# RK3399-AP register map
File version: 1
CPU: CA7 r0p1, little endian, MPU, FPU, I-cache, D-cache, VTOR, 4 interrupt priority bits, 0 interrupts
Registers are 32-bit, read-write, reset 0x0 unless marked. A register's access mark holds for its fields unless they carry their own. Offsets are from the block's base; [hi:lo] are bit positions; 'fields as' and 'values as' point back to an identical list.

## GRF (part 2 of 4)
Base 0xFF770000
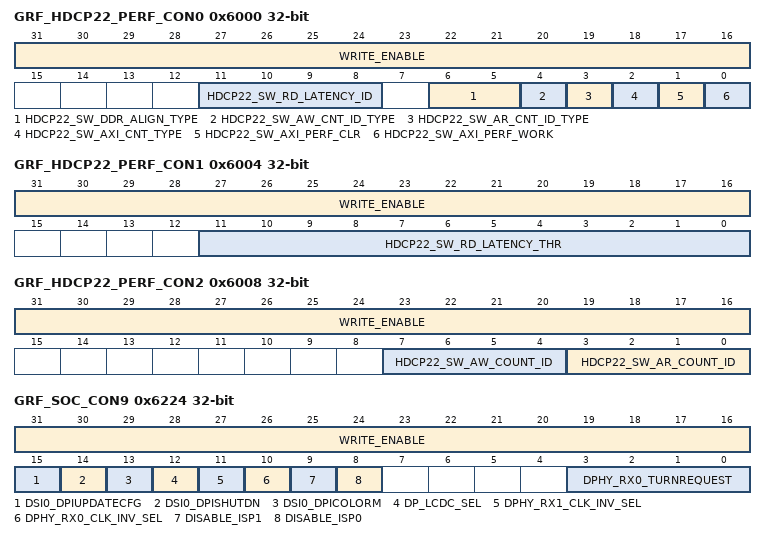
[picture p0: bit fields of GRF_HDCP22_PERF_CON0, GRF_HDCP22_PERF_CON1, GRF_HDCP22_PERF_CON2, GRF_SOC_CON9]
0x6000 GRF_HDCP22_PERF_CON0 — hdcp performance monitor control register
  [31:16] WRITE_ENABLE — bit0~15 write enable When bit 16=1, bit 0 can be written by software . When bit 16=0, bit 0 cannot be written by software; When bit 17=1, bit 1 can be written by software . When bit 17=0, bit 1 cannot be written by software; ...... When bit 31=1, bit 15 can be written by software . When bit 31=0, bit 15 cannot be written by software;
  [11:8] HDCP22_SW_RD_LATENCY_ID — Axi read channel id for latency AXI_PERFormance test
  [6:5] HDCP22_SW_DDR_ALIGN_TYPE — 0: 16-Byte align 1: 32-Byte align 2: 64-Byte align 3: 128-Byte align
  [4] HDCP22_SW_AW_CNT_ID_TYPE — 0: count all write channels 1: count sw_aw_count_id write channel only
  [3] HDCP22_SW_AR_CNT_ID_TYPE — axi_perf counter id control 0: count all read channel id 1: count sw_ar_count_id read channel only
  [2] HDCP22_SW_AXI_CNT_TYPE — axi_perf counter type 0: axi transfer test 1: ddr align transfer test
  [1] HDCP22_SW_AXI_PERF_CLR — axi_perf clear bit 0: disable 1: enable
  [0] HDCP22_SW_AXI_PERF_WORK — axi_perf enable bit 0: disable 1: enable
0x6004 GRF_HDCP22_PERF_CON1 — hdcp performance monitor control register
  [31:16] WRITE_ENABLE — bit0~15 write enable When bit 16=1, bit 0 can be written by software . When bit 16=0, bit 0 cannot be written by software; When bit 17=1, bit 1 can be written by software . When bit 17=0, bit 1 cannot be written by software; ...... When bit 31=1, bit 15 can be written by software . When bit 31=0, bit 15 cannot be written by software;
  [11:0] HDCP22_SW_RD_LATENCY_THR — Axi Read latency threshold
0x6008 GRF_HDCP22_PERF_CON2 — hdcp performance monitor control register
  [31:16] WRITE_ENABLE — bit0~15 write enable When bit 16=1, bit 0 can be written by software . When bit 16=0, bit 0 cannot be written by software; When bit 17=1, bit 1 can be written by software . When bit 17=0, bit 1 cannot be written by software; ...... When bit 31=1, bit 15 can be written by software . When bit 31=0, bit 15 cannot be written by software;
  [7:4] HDCP22_SW_AW_COUNT_ID — When sw_aw_cnt_id_type=1, only count the id designated by sw_aw_count_id
  [3:0] HDCP22_SW_AR_COUNT_ID — When sw_ar_cnt_id_type=1, only count the id designated by sw_ar_count_id
0x600C GRF_HDCP22_PERF_RD_MAX_LATENCY_NUM — hdcp performance monitor status register
  [12:0] RD_MAX_LATENCY_R — axi read max latency output
0x6010 GRF_HDCP22_PERF_RD_LATENCY_SAMP_NUM — hdcp performance monitor status register
  [26:0] RD_LATENCY_SAMP_R — AXI read latency total sample number
0x6014 GRF_HDCP22_PERF_RD_LATENCY_ACC_NUM — hdcp performance monitor status register
  [31:0] RD_LATENCY_ACC_CNT_R — AXI read latency (>sw_rd_latency_thr) total number
0x6018 GRF_HDCP22_PERF_RD_AXI_TOTAL_BYTE — hdcp performance monitor status register
  [31:0] RD_AXI_TOTAL_BYTE — AXI active total read bytes/ddr align read bytes
0x601C GRF_HDCP22_PERF_WR_AXI_TOTAL_BYTE — hdcp performance monitor status register
  [31:0] WR_AXI_TOTAL_BYTE — AXI active total write bytes/ddr align write bytes
0x6020 GRF_HDCP22_PERF_WORKING_CNT — hdcp performance monitor status register
  [31:0] WORKING_CNT_R — working counter
0x6224 GRF_SOC_CON9 — SoC control register 9
  [31:16] WRITE_ENABLE — bit0~15 write enable When bit 16=1, bit 0 can be written by software . When bit 16=0, bit 0 cannot be written by software; When bit 17=1, bit 1 can be written by software . When bit 17=0, bit 1 cannot be written by software; ...... When bit 31=1, bit 15 can be written by software . When bit 31=0, bit 15 cannot be written by software;
  [15] DSI0_DPIUPDATECFG — DSI host0 dpiupdatecfg bit control
  [14] DSI0_DPISHUTDN — DSI0 dpishutdn bit control
  [13] DSI0_DPICOLORM — DSI0 dpicolorm bit control
  [12] DP_LCDC_SEL — dp lcdc select 1\'b0: vop big 1\'b1: vop little
  [11] DPHY_RX1_CLK_INV_SEL — dphy rx1 clock inveter select bit
  [10] DPHY_RX0_CLK_INV_SEL — dphy rx0 clock inveter select bit
  [9] DISABLE_ISP1 — isp1 disable control
  [8] DISABLE_ISP0 — isp0 disable control
  [3:0] DPHY_RX0_TURNREQUEST — dphy rx0 runrequest port control
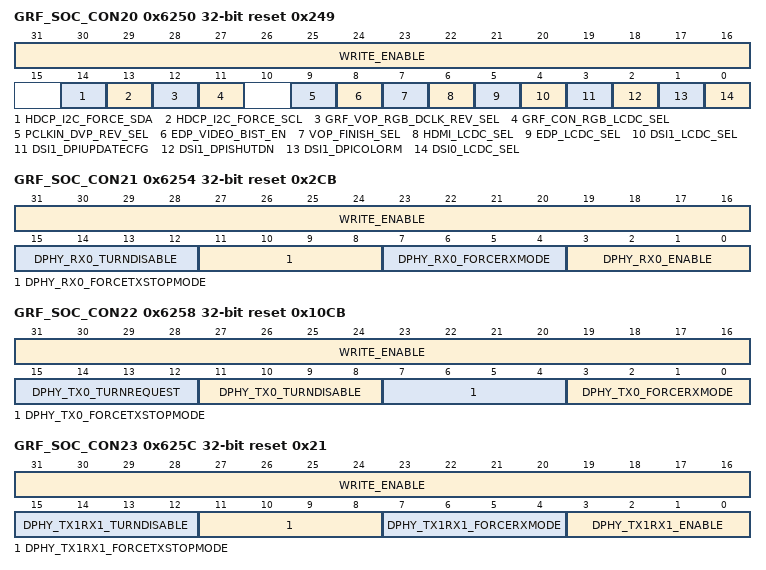
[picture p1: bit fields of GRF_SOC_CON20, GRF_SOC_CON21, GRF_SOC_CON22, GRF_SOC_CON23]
0x6250 GRF_SOC_CON20 reset 0x249 — SoC control register 20
  [31:16] WRITE_ENABLE — bit0~15 write enable When bit 16=1, bit 0 can be written by software . When bit 16=0, bit 0 cannot be written by software; When bit 17=1, bit 1 can be written by software . When bit 17=0, bit 1 cannot be written by software; ...... When bit 31=1, bit 15 can be written by software . When bit 31=0, bit 15 cannot be written by software;
  [14] HDCP_I2C_FORCE_SDA — hdcp_i2c_force_sda bit control
  [13] HDCP_I2C_FORCE_SCL — hdcp_i2c_force_scl control
  [12] GRF_VOP_RGB_DCLK_REV_SEL — dclk phase selct 0: 0 degree 1: 180 degree
  [11] GRF_CON_RGB_LCDC_SEL — vop select 1\'b0: vop big 1\'b1: vop little
  [9] PCLKIN_DVP_REV_SEL — pclkin dvp clock select 0: not invet phase 1: invert phase
  [8] EDP_VIDEO_BIST_EN — edp video bist enable 1: enable 0: disable
  [7] VOP_FINISH_SEL — vop finish select 1\'b0: vop big 1\'b1: vop little
  [6] HDMI_LCDC_SEL — hdmi lcdc select 1\'b0: vop big 1\'b1: vop little
  [5] EDP_LCDC_SEL — edp lcdc select 1\'b0: vop big 1\'b1: vop little
  [4] DSI1_LCDC_SEL — dsi1 lcdc select 1\'b0: vop big 1\'b1: vop little
  [3] DSI1_DPIUPDATECFG — dsi1 dpiupdatecfg bit control
  [2] DSI1_DPISHUTDN — dsi1 dpishutdn bit control
  [1] DSI1_DPICOLORM — dsi1 dpicolorm bit control
  [0] DSI0_LCDC_SEL — dsi0 vol select bit 1\'b0: vop big 1\'b1: vop little
0x6254 GRF_SOC_CON21 reset 0x2CB — SoC control register 21
  [31:16] WRITE_ENABLE — bit0~15 write enable When bit 16=1, bit 0 can be written by software . When bit 16=0, bit 0 cannot be written by software; When bit 17=1, bit 1 can be written by software . When bit 17=0, bit 1 cannot be written by software; ...... When bit 31=1, bit 15 can be written by software . When bit 31=0, bit 15 cannot be written by software;
  [15:12] DPHY_RX0_TURNDISABLE — dphy_rx0_turndisable bit control
  [11:8] DPHY_RX0_FORCETXSTOPMODE — dphy_rx0_forcetxstopmode bit control
  [7:4] DPHY_RX0_FORCERXMODE — dphy_rx0_forcerxmode bit control
  [3:0] DPHY_RX0_ENABLE — dphy_rx0_enable bit control
0x6258 GRF_SOC_CON22 reset 0x10CB — SoC control register 22
  [31:16] WRITE_ENABLE — bit0~15 write enable When bit 16=1, bit 0 can be written by software . When bit 16=0, bit 0 cannot be written by software; When bit 17=1, bit 1 can be written by software . When bit 17=0, bit 1 cannot be written by software; ...... When bit 31=1, bit 15 can be written by software . When bit 31=0, bit 15 cannot be written by software;
  [15:12] DPHY_TX0_TURNREQUEST — dphy_tx0_turnrequest bit control
  [11:8] DPHY_TX0_TURNDISABLE — dphy_tx0_turndisable bit control
  [7:4] DPHY_TX0_FORCETXSTOPMODE — dphy_tx0_forcetxstopmode bit control
  [3:0] DPHY_TX0_FORCERXMODE — dphy_tx0_forcerxmode bit control
0x625C GRF_SOC_CON23 reset 0x21 — SoC control register 23
  [31:16] WRITE_ENABLE — bit0~15 write enable When bit 16=1, bit 0 can be written by software . When bit 16=0, bit 0 cannot be written by software; When bit 17=1, bit 1 can be written by software . When bit 17=0, bit 1 cannot be written by software; ...... When bit 31=1, bit 15 can be written by software . When bit 31=0, bit 15 cannot be written by software;
  [15:12] DPHY_TX1RX1_TURNDISABLE — dphy_tx1rx1_turndisable bit control
  [11:8] DPHY_TX1RX1_FORCETXSTOPMODE — dphy_tx1rx1_forcetxstopmode bit control
  [7:4] DPHY_TX1RX1_FORCERXMODE — dphy_tx1rx1_forcerxmode bit control
  [3:0] DPHY_TX1RX1_ENABLE — dphy_tx1rx1_enable bit control
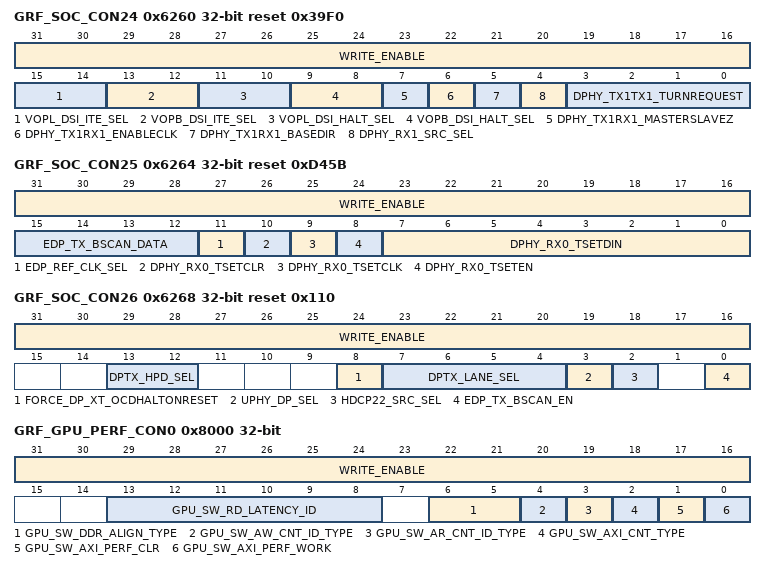
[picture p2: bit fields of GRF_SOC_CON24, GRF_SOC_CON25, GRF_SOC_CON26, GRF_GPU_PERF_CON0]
0x6260 GRF_SOC_CON24 reset 0x39F0 — SoC control register 24
  [31:16] WRITE_ENABLE — bit0~15 write enable When bit 16=1, bit 0 can be written by software . When bit 16=0, bit 0 cannot be written by software; When bit 17=1, bit 1 can be written by software . When bit 17=0, bit 1 cannot be written by software; ...... When bit 31=1, bit 15 can be written by software . When bit 31=0, bit 15 cannot be written by software;
  [15:14] VOPL_DSI_ITE_SEL — vopl_dsi_ite_sel bit control 0: mipi_dsi0_edpite 1: mipi_dsi1_edpite 2: 0 3: 1
  [13:12] VOPB_DSI_ITE_SEL — vopb_dsi_ite_sel bit control 0: mipi_dsi0_edpite 1: mipi_dsi1_edpite 2: 0 3: 1
  [11:10] VOPL_DSI_HALT_SEL — vopl_dsi_halt_sel bit control 0: mipi_dsi0_edpihalt 1: mipi_dsi0_edpihalt 2: low 3: high
  [9:8] VOPB_DSI_HALT_SEL — vopb_dsi_halt_sel bit control 0: mipi_dsi0_edpihalt 1: mipi_dsi0_edpihalt 2: low 3: high
  [7] DPHY_TX1RX1_MASTERSLAVEZ — dphy_tx1rx1_masterslavez bit control
  [6] DPHY_TX1RX1_ENABLECLK — dphy_tx1rx1_enableclk bit control
  [5] DPHY_TX1RX1_BASEDIR — dphy_tx1rx1_basedir bit control
  [4] DPHY_RX1_SRC_SEL — dphy_rx1_src_sel bit control
  [3:0] DPHY_TX1TX1_TURNREQUEST — dphy_tx1tx1_turnrequest bit control
0x6264 GRF_SOC_CON25 reset 0xD45B — SoC control register 25
  [31:16] WRITE_ENABLE — bit0~15 write enable When bit 16=1, bit 0 can be written by software . When bit 16=0, bit 0 cannot be written by software; When bit 17=1, bit 1 can be written by software . When bit 17=0, bit 1 cannot be written by software; ...... When bit 31=1, bit 15 can be written by software . When bit 31=0, bit 15 cannot be written by software;
  [15:12] EDP_TX_BSCAN_DATA — edp_tx_bscan_data bit control
  [11] EDP_REF_CLK_SEL — edp_ref_clk_sel bit control
  [10] DPHY_RX0_TSETCLR — dphy_rx0_tsetclr bit control
  [9] DPHY_RX0_TSETCLK — dphy_rx0_tsetclk bit control
  [8] DPHY_RX0_TSETEN — dphy_rx0_tseten bit control
  [7:0] DPHY_RX0_TSETDIN — dphy_rx0_tsetdin bit control
0x6268 GRF_SOC_CON26 reset 0x110 — SoC control register 26
  [31:16] WRITE_ENABLE — bit0~15 write enable When bit 16=1, bit 0 can be written by software . When bit 16=0, bit 0 cannot be written by software; When bit 17=1, bit 1 can be written by software . When bit 17=0, bit 1 cannot be written by software; ...... When bit 31=1, bit 15 can be written by software . When bit 31=0, bit 15 cannot be written by software;
  [13:12] DPTX_HPD_SEL — dptx_hpd_sel bit control
  [8] FORCE_DP_XT_OCDHALTONRESET — force_dp_xt_ocdhaltonreset bit control
  [7:4] DPTX_LANE_SEL — dptx_lane_sel bit control
  [3] UPHY_DP_SEL — uphy_dp_sel bit control
  [2] HDCP22_SRC_SEL — hdcp22_src_sel bit control
  [0] EDP_TX_BSCAN_EN — edp_tx_bscan_en bit control
0x8000 GRF_GPU_PERF_CON0 — gpu performance monitor control register
  [31:16] WRITE_ENABLE — bit0~15 write enable When bit 16=1, bit 0 can be written by software . When bit 16=0, bit 0 cannot be written by software; When bit 17=1, bit 1 can be written by software . When bit 17=0, bit 1 cannot be written by software; ...... When bit 31=1, bit 15 can be written by software . When bit 31=0, bit 15 cannot be written by software;
  [13:8] GPU_SW_RD_LATENCY_ID — Axi read channel id for latency AXI_PERFormance test
  [6:5] GPU_SW_DDR_ALIGN_TYPE — 0: 16-Byte align 1: 32-Byte align 2: 64-Byte align 3: 128-Byte align
  [4] GPU_SW_AW_CNT_ID_TYPE — axi_perf counter id control 0: count all write channel id 1: count sw_ar_count_id write channel only
  [3] GPU_SW_AR_CNT_ID_TYPE — axi_perf counter id control 0: count all read channel id 1: count sw_ar_count_id read channel only
  [2] GPU_SW_AXI_CNT_TYPE — axi_perf counter type 0: axi transfer test 1: ddr align transfer test
  [1] GPU_SW_AXI_PERF_CLR — axi_perf clear bit 0: disable 1: enable
  [0] GPU_SW_AXI_PERF_WORK — axi_perf enable bit 0: disable 1: enable
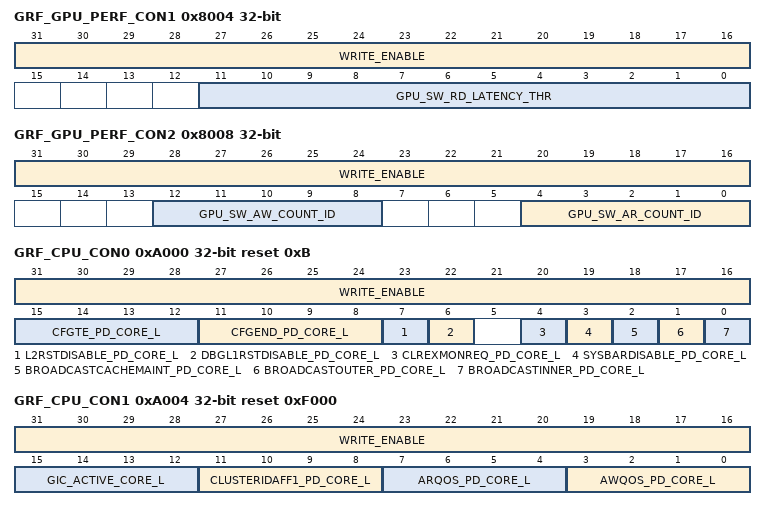
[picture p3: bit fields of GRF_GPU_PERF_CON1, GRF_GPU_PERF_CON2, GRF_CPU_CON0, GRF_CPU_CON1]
0x8004 GRF_GPU_PERF_CON1 — gpu performance monitor control register
  [31:16] WRITE_ENABLE — bit0~15 write enable When bit 16=1, bit 0 can be written by software . When bit 16=0, bit 0 cannot be written by software; When bit 17=1, bit 1 can be written by software . When bit 17=0, bit 1 cannot be written by software; ...... When bit 31=1, bit 15 can be written by software . When bit 31=0, bit 15 cannot be written by software;
  [11:0] GPU_SW_RD_LATENCY_THR — Axi read channel id for latency AXI_PERFormance test
0x8008 GRF_GPU_PERF_CON2 — gpu performance monitor control register
  [31:16] WRITE_ENABLE — bit0~15 write enable When bit 16=1, bit 0 can be written by software . When bit 16=0, bit 0 cannot be written by software; When bit 17=1, bit 1 can be written by software . When bit 17=0, bit 1 cannot be written by software; ...... When bit 31=1, bit 15 can be written by software . When bit 31=0, bit 15 cannot be written by software;
  [12:8] GPU_SW_AW_COUNT_ID — When sw_aw_cnt_id_type=1, only count the id designated by sw_aw_count_id
  [4:0] GPU_SW_AR_COUNT_ID — When sw_ar_cnt_id_type=1, only count the id designated by sw_ar_count_id
0x800C GRF_GPU_PERF_RD_MAX_LATENCY_NUM — gpu performance monitor status register
  [12:0] RD_MAX_LATENCY_R — axi read max latency output
0x8010 GRF_GPU_PERF_RD_LATENCY_SAMP_NUM — gpu performance monitor status register
  [26:0] RD_LATENCY_SAMP_R — AXI read latency total sample number
0x8014 GRF_GPU_PERF_RD_LATENCY_ACC_NUM — gpu performance monitor status register
  fields as GRF_HDCP22_PERF_RD_LATENCY_ACC_NUM
0x8018 GRF_GPU_PERF_RD_AXI_TOTAL_BYTE — gpu performance monitor status register
  fields as GRF_HDCP22_PERF_RD_AXI_TOTAL_BYTE
0x801C GRF_GPU_PERF_WR_AXI_TOTAL_BYTE — gpu performance monitor status register
  fields as GRF_HDCP22_PERF_WR_AXI_TOTAL_BYTE
0x8020 GRF_GPU_PERF_WORKING_CNT — gpu performance monitor status register
  [31:0] WORKING_CNT_R — working counter
0xA000 GRF_CPU_CON0 reset 0xB — cpu control register 0
  [31:16] WRITE_ENABLE — bit0~15 write enable When bit 16=1, bit 0 can be written by software . When bit 16=0, bit 0 cannot be written by software; When bit 17=1, bit 1 can be written by software . When bit 17=0, bit 1 cannot be written by software; ...... When bit 31=1, bit 15 can be written by software . When bit 31=0, bit 15 cannot be written by software;
  [15:12] CFGTE_PD_CORE_L — pd_core_l cpu cfgte bit control 0: disable 1: enable
  [11:8] CFGEND_PD_CORE_L — pd_core_l cpu cfgend bit control 0: disable 1: enable
  [7] L2RSTDISABLE_PD_CORE_L — pd_core_l cpu l2rstdisable bit control 0: disable 1: enable
  [6] DBGL1RSTDISABLE_PD_CORE_L — pd_core_l cpu dbgl1rstdisable bit control 0: disable 1: enable
  [4] CLREXMONREQ_PD_CORE_L — pd_core_l cpu clrexmonreq bit control 0: disable 1: enable
  [3] SYSBARDISABLE_PD_CORE_L — pd_core_l cpu sysbardisable bit control 0: disable 1: enable
  [2] BROADCASTCACHEMAINT_PD_CORE_L — pd_core_l cpu broadcastcachemaint bit control 0: disable 1: enable
  [1] BROADCASTOUTER_PD_CORE_L — pd_core_l cpu broadcastouter bit control 0: disable 1: enable
  [0] BROADCASTINNER_PD_CORE_L — pd_core_l cpu broadcastinner bit control 1: enable 0: disable
0xA004 GRF_CPU_CON1 reset 0xF000 — cpu control register 1
  [31:16] WRITE_ENABLE — bit0~15 write enable When bit 16=1, bit 0 can be written by software . When bit 16=0, bit 0 cannot be written by software; When bit 17=1, bit 1 can be written by software . When bit 17=0, bit 1 cannot be written by software; ...... When bit 31=1, bit 15 can be written by software . When bit 31=0, bit 15 cannot be written by software;
  [15:12] GIC_ACTIVE_CORE_L — pd_core_l gic_active bit control
  [11:8] CLUSTERIDAFF1_PD_CORE_L — pd_core_l clusteridaff1 bit control
  [7:4] ARQOS_PD_CORE_L — pd_core_l arqos bit control
  [3:0] AWQOS_PD_CORE_L — pd_core_l awqos bit control
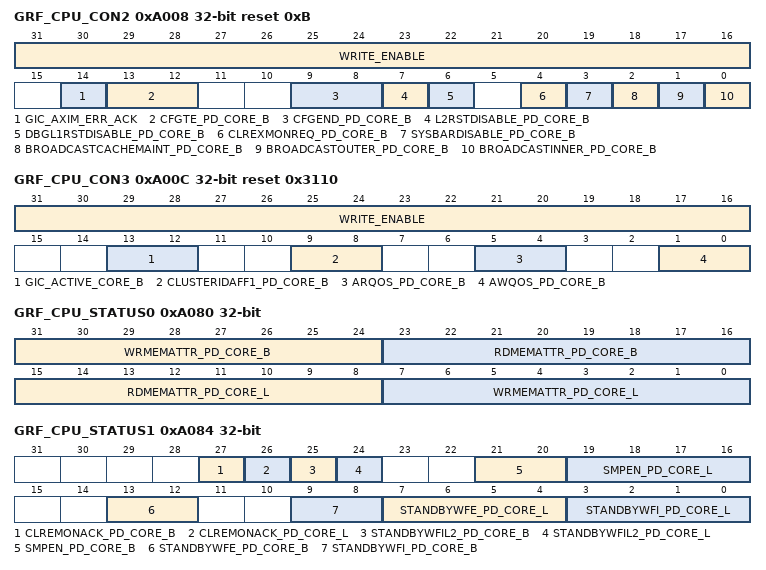
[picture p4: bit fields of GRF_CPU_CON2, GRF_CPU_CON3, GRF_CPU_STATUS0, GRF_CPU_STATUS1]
0xA008 GRF_CPU_CON2 reset 0xB — cpu control register 2
  [31:16] WRITE_ENABLE — bit0~15 write enable When bit 16=1, bit 0 can be written by software . When bit 16=0, bit 0 cannot be written by software; When bit 17=1, bit 1 can be written by software . When bit 17=0, bit 1 cannot be written by software; ...... When bit 31=1, bit 15 can be written by software . When bit 31=0, bit 15 cannot be written by software;
  [14] GIC_AXIM_ERR_ACK — gic axi master error acknowledges 0: disable 1: enable
  [13:12] CFGTE_PD_CORE_B — pd_core_b cpu cfgte bit control 0: disable 1: enable
  [9:8] CFGEND_PD_CORE_B — pd_core_b cpu cfgend bit control 0: disable 1: enable
  [7] L2RSTDISABLE_PD_CORE_B — pd_core_b cpu l2rstdisable bit control 0: disable 1: enable
  [6] DBGL1RSTDISABLE_PD_CORE_B — pd_core_b cpu dbgl1rstdisable bit control 0: disable 1: enable
  [4] CLREXMONREQ_PD_CORE_B — pd_core_b cpu clrexmonreq bit control 0: disable 1: enable
  [3] SYSBARDISABLE_PD_CORE_B — pd_core_b cpu sysbardisable bit control 0: disable 1: enable
  [2] BROADCASTCACHEMAINT_PD_CORE_B — pd_core_b cpu broadcastcachemaint bit control 0: disable 1: enable
  [1] BROADCASTOUTER_PD_CORE_B — pd_core_b cpu broadcastouter bit control 0: disable 1: enable
  [0] BROADCASTINNER_PD_CORE_B — pd_core_b cpu broadcastinner bit control 1: enable 0: disable
0xA00C GRF_CPU_CON3 reset 0x3110 — cpu control register 3
  [31:16] WRITE_ENABLE — bit0~15 write enable When bit 16=1, bit 0 can be written by software . When bit 16=0, bit 0 cannot be written by software; When bit 17=1, bit 1 can be written by software . When bit 17=0, bit 1 cannot be written by software; ...... When bit 31=1, bit 15 can be written by software . When bit 31=0, bit 15 cannot be written by software;
  [13:12] GIC_ACTIVE_CORE_B — pd_core_b gic_active bit control
  [9:8] CLUSTERIDAFF1_PD_CORE_B — pd_core_b clusteridaff1 bit control
  [5:4] ARQOS_PD_CORE_B — pd_core_b arqos bit control
  [1:0] AWQOS_PD_CORE_B — pd_core_b awqos bit control
0xA080 GRF_CPU_STATUS0 — cpu status register 0
  [31:24] WRMEMATTR_PD_CORE_B — wrmemattr of pd_core_b status
  [23:16] RDMEMATTR_PD_CORE_B — rdmemattr of pd_core_b status
  [15:8] RDMEMATTR_PD_CORE_L — rdmemattr of pd_core_l status
  [7:0] WRMEMATTR_PD_CORE_L — wrmemattr of pd_core_l status
0xA084 GRF_CPU_STATUS1 — cpu status register 1
  [27] CLREMONACK_PD_CORE_B — the status of clremonack_pd_core_b
  [26] CLREMONACK_PD_CORE_L — the status of clremonack_pd_core_l
  [25] STANDBYWFIL2_PD_CORE_B — standbywfil2 of pd_core_b status bit
  [24] STANDBYWFIL2_PD_CORE_L — standbywfil2 of pd_core_l status bit
  [21:20] SMPEN_PD_CORE_B — status of smpen_pd_core_b
  [19:16] SMPEN_PD_CORE_L — status of smpen_pd_core_l
  [13:12] STANDBYWFE_PD_CORE_B — standbywfe of pd_core_b status bit
  [9:8] STANDBYWFI_PD_CORE_B — standbywfi of pd_core_b status bit
  [7:4] STANDBYWFE_PD_CORE_L — standbywfe of pd_core_l status bit
  [3:0] STANDBYWFI_PD_CORE_L — standbywfi of pd_core_l status bit
0xA088 GRF_CPU_STATUS2 — cpu status register 2
  [31:0] CCI_EVENT_BUS — the status of cci_event_bus[31:0]
0xA08C GRF_CPU_STATUS3 — cpu status register 3
  [31:0] CCI_EVENT_BUS — the status of cci_event_bus[63:32]
0xA090 GRF_CPU_STATUS4 — cpu status register 4
  [29:0] CCI_EVENT_BUS — the status of cci_event_bus[93:64]
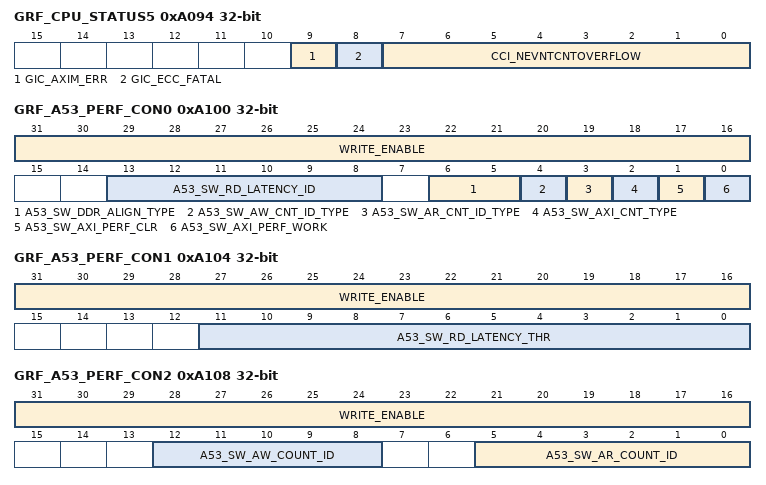
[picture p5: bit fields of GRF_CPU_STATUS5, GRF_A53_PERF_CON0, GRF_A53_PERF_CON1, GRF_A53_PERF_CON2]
0xA094 GRF_CPU_STATUS5 — cpu status register 5
  [9] GIC_AXIM_ERR — gic_axim_err status bit
  [8] GIC_ECC_FATAL — gic_ecc_fatal status bit
  [7:0] CCI_NEVNTCNTOVERFLOW — cci_nevntcntoverflow status bit
0xA100 GRF_A53_PERF_CON0 — a53 performance monitor control register
  [31:16] WRITE_ENABLE — bit0~15 write enable When bit 16=1, bit 0 can be written by software . When bit 16=0, bit 0 cannot be written by software; When bit 17=1, bit 1 can be written by software . When bit 17=0, bit 1 cannot be written by software; ...... When bit 31=1, bit 15 can be written by software . When bit 31=0, bit 15 cannot be written by software;
  [13:8] A53_SW_RD_LATENCY_ID — Axi read channel id for latency AXI_PERFormance test
  [6:5] A53_SW_DDR_ALIGN_TYPE — 0: 16-Byte align 1: 32-Byte align 2: 64-Byte align 3: 128-Byte align
  [4] A53_SW_AW_CNT_ID_TYPE — axi_perf counter id control 0: count all write channel id 1: count sw_ar_count_id write channel only
  [3] A53_SW_AR_CNT_ID_TYPE — axi_perf counter id control 0: count all read channel id 1: count sw_ar_count_id read channel only
  [2] A53_SW_AXI_CNT_TYPE — axi_perf counter type 0: axi transfer test 1: ddr align transfer test
  [1] A53_SW_AXI_PERF_CLR — axi_perf clear bit 0: disable 1: enable
  [0] A53_SW_AXI_PERF_WORK — a53 performance monitor control register axi_perf enable bit 0: disable 1: enable
0xA104 GRF_A53_PERF_CON1 — a53 performance monitor control register
  [31:16] WRITE_ENABLE — bit0~15 write enable When bit 16=1, bit 0 can be written by software . When bit 16=0, bit 0 cannot be written by software; When bit 17=1, bit 1 can be written by software . When bit 17=0, bit 1 cannot be written by software; ...... When bit 31=1, bit 15 can be written by software . When bit 31=0, bit 15 cannot be written by software;
  [11:0] A53_SW_RD_LATENCY_THR — Axi read channel id for latency AXI_PERFormance test
0xA108 GRF_A53_PERF_CON2 — a53 performance monitor control register
  [31:16] WRITE_ENABLE — bit0~15 write enable When bit 16=1, bit 0 can be written by software . When bit 16=0, bit 0 cannot be written by software; When bit 17=1, bit 1 can be written by software . When bit 17=0, bit 1 cannot be written by software; ...... When bit 31=1, bit 15 can be written by software . When bit 31=0, bit 15 cannot be written by software;
  [12:8] A53_SW_AW_COUNT_ID — When sw_aw_cnt_id_type=1, only count the id designated by sw_aw_count_id
  [5:0] A53_SW_AR_COUNT_ID — When sw_ar_cnt_id_type=1, only count the id designated by sw_ar_count_id
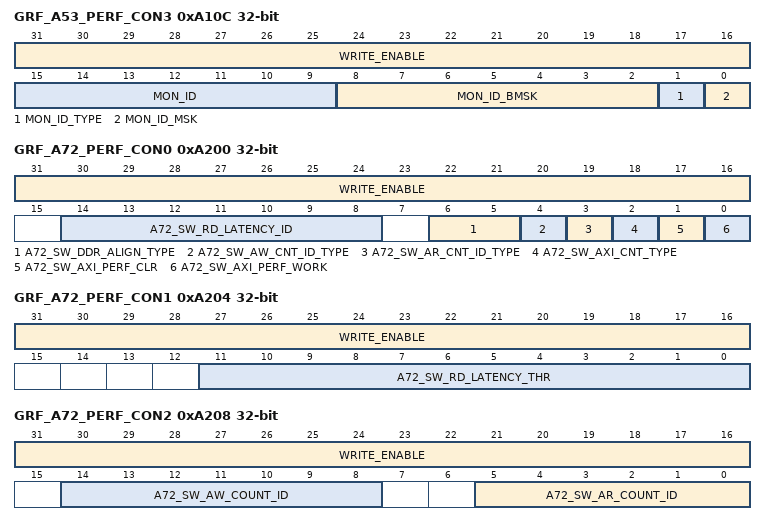
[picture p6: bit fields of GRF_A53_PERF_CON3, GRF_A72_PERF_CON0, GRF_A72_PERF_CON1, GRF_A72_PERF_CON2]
0xA10C GRF_A53_PERF_CON3 — a53 performance monitor control register
  [31:16] WRITE_ENABLE — bit0~15 write enable When bit 16=1, bit 0 can be written by software . When bit 16=0, bit 0 cannot be written by software; When bit 17=1, bit 1 can be written by software . When bit 17=0, bit 1 cannot be written by software; ...... When bit 31=1, bit 15 can be written by software . When bit 31=0, bit 15 cannot be written by software;
  [15:9] MON_ID — mon_id bit control
  [8:2] MON_ID_BMSK — mon_id_bmsk bit control
  [1] MON_ID_TYPE — mon_id_type bit control
  [0] MON_ID_MSK — mon_id_msk bit control
0xA110 GRF_A53_PERF_RD_MON_ST — performance monitor read start address
  [31:0] RD_START_ADDR — monitor read start address
0xA114 GRF_A53_PERF_RD_MON_END — performance monitor end address
  [31:0] RD_END_ADDR — monitor read end address
0xA118 GRF_A53_PERF_WR_MON_ST — performance write monitor start address
  [31:0] WR_START_ADDR — monitor write start address
0xA11C GRF_A53_PERF_WR_MON_END — performance monitor write end address
  [31:0] WR_END_ADDR — monitor write end address
0xA120 GRF_A53_PERF_RD_MAX_LATENCY_NUM — a53 performance monitor status register
  [12:0] RD_MAX_LATENCY_R — axi read max latency output
0xA124 GRF_A53_PERF_RD_LATENCY_SAMP_NUM — a53 performance monitor status register
  [26:0] RD_LATENCY_SAMP_R — AXI read latency total sample number
0xA128 GRF_A53_PERF_RD_LATENCY_ACC_NUM — a53 performance monitor status register
  fields as GRF_HDCP22_PERF_RD_LATENCY_ACC_NUM
0xA12C GRF_A53_PERF_RD_AXI_TOTAL_BYTE — a53 performance monitor status register
  fields as GRF_HDCP22_PERF_RD_AXI_TOTAL_BYTE
0xA130 GRF_A53_PERF_WR_AXI_TOTAL_BYTE — a53 performance monitor status register
  fields as GRF_HDCP22_PERF_WR_AXI_TOTAL_BYTE
0xA134 GRF_A53_PERF_WORKING_CNT — a53 performance monitor status register
  [31:0] WORKING_CNT_R — working counter
0xA138 GRF_A53_PERF_INT_STATUS — a53 performance monitor status register
  [0] INT_STATUS — interrupt status bit
0xA200 GRF_A72_PERF_CON0 — a72 performance monitor control register
  [31:16] WRITE_ENABLE — bit0~15 write enable When bit 16=1, bit 0 can be written by software . When bit 16=0, bit 0 cannot be written by software; When bit 17=1, bit 1 can be written by software . When bit 17=0, bit 1 cannot be written by software; ...... When bit 31=1, bit 15 can be written by software . When bit 31=0, bit 15 cannot be written by software;
  [14:8] A72_SW_RD_LATENCY_ID — Axi read channel id for latency AXI_PERFormance test
  [6:5] A72_SW_DDR_ALIGN_TYPE — 0: 16-Byte align 1: 32-Byte align 2: 64-Byte align 3: 128-Byte align
  [4] A72_SW_AW_CNT_ID_TYPE — axi_perf counter id control 0: count all write channel id 1: count sw_ar_count_id write channel only
  [3] A72_SW_AR_CNT_ID_TYPE — axi_perf counter id control 0: count all read channel id 1: count sw_ar_count_id read channel only
  [2] A72_SW_AXI_CNT_TYPE — axi_perf counter type 0: axi transfer test 1: ddr align transfer test
  [1] A72_SW_AXI_PERF_CLR — axi_perf clear bit 0: disable 1: enable
  [0] A72_SW_AXI_PERF_WORK — axi_perf enable bit 0: disable 1: enable
0xA204 GRF_A72_PERF_CON1 — a72 performance monitor control register
  [31:16] WRITE_ENABLE — bit0~15 write enable When bit 16=1, bit 0 can be written by software . When bit 16=0, bit 0 cannot be written by software; When bit 17=1, bit 1 can be written by software . When bit 17=0, bit 1 cannot be written by software; ...... When bit 31=1, bit 15 can be written by software . When bit 31=0, bit 15 cannot be written by software;
  [11:0] A72_SW_RD_LATENCY_THR — Axi read channel id for latency AXI_PERFormance test
0xA208 GRF_A72_PERF_CON2 — a72 performance monitor control register
  [31:16] WRITE_ENABLE — bit0~15 write enable When bit 16=1, bit 0 can be written by software . When bit 16=0, bit 0 cannot be written by software; When bit 17=1, bit 1 can be written by software . When bit 17=0, bit 1 cannot be written by software; ...... When bit 31=1, bit 15 can be written by software . When bit 31=0, bit 15 cannot be written by software;
  [14:8] A72_SW_AW_COUNT_ID — When sw_aw_cnt_id_type=1, only count the id designated by sw_aw_count_id
  [5:0] A72_SW_AR_COUNT_ID — When sw_ar_cnt_id_type=1, only count the id designated by sw_ar_count_id
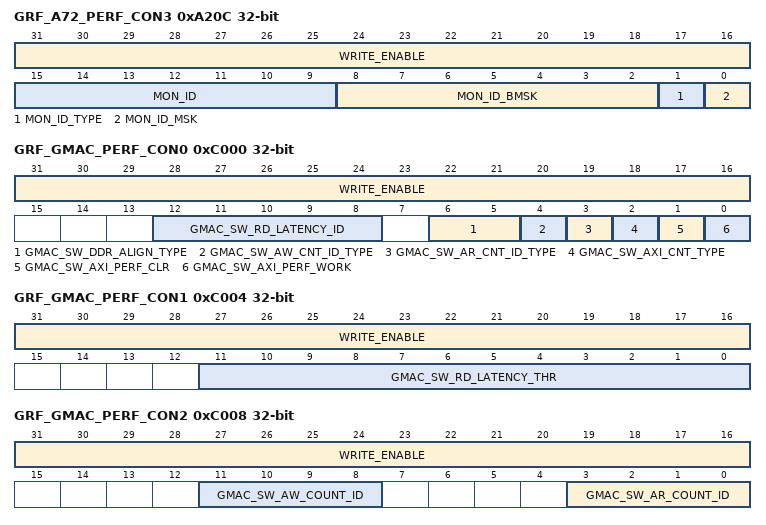
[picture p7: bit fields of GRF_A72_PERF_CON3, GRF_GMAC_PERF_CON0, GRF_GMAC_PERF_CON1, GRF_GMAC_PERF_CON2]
0xA20C GRF_A72_PERF_CON3 — a72 performance monitor control register
  fields as GRF_A53_PERF_CON3
0xA210 GRF_A72_PERF_RD_MON_ST — performance monitor read start address
  [31:0] RD_START_ADDR — monitor read start address
0xA214 GRF_A72_PERF_RD_MON_END — performance monitor end address
  [31:0] RD_END_ADDR — monitor read end address
0xA218 GRF_A72_PERF_WR_MON_ST — performance write monitor start address
  [31:0] WR_START_ADDR — monitor write start address
0xA21C GRF_A72_PERF_WR_MON_END — performance monitor write end address
  [31:0] WR_END_ADDR — monitor write end address
0xA220 GRF_A72_PERF_RD_MAX_LATENCY_NUM — a72 performance monitor status register
  [12:0] RD_MAX_LATENCY_R — axi read max latency output
0xA224 GRF_A72_PERF_RD_LATENCY_SAMP_NUM — a72 performance monitor status register
  [26:0] RD_LATENCY_SAMP_R — AXI read latency total sample number
0xA228 GRF_A72_PERF_RD_LATENCY_ACC_NUM — a72 performance monitor status register
  fields as GRF_HDCP22_PERF_RD_LATENCY_ACC_NUM
0xA22C GRF_A72_PERF_RD_AXI_TOTAL_BYTE — a72 performance monitor status register
  fields as GRF_HDCP22_PERF_RD_AXI_TOTAL_BYTE
0xA230 GRF_A72_PERF_WR_AXI_TOTAL_BYTE — a72 performance monitor status register
  fields as GRF_HDCP22_PERF_WR_AXI_TOTAL_BYTE
0xA234 GRF_A72_PERF_WORKING_CNT — a72 performance monitor status register
  [31:0] WORKING_CNT_R — working counter
0xA238 GRF_A72_PERF_INT_STATUS — a72 performance monitor status register
  [0] INT_STATUS — interrupt status bit
0xC000 GRF_GMAC_PERF_CON0 — gmac performance monitor control register
  [31:16] WRITE_ENABLE — bit0~15 write enable When bit 16=1, bit 0 can be written by software . When bit 16=0, bit 0 cannot be written by software; When bit 17=1, bit 1 can be written by software . When bit 17=0, bit 1 cannot be written by software; ...... When bit 31=1, bit 15 can be written by software . When bit 31=0, bit 15 cannot be written by software;
  [12:8] GMAC_SW_RD_LATENCY_ID — Axi read channel id for latency AXI_PERFormance test
  [6:5] GMAC_SW_DDR_ALIGN_TYPE — 0: 16-Byte align 1: 32-Byte align 2: 64-Byte align 3: 128-Byte align
  [4] GMAC_SW_AW_CNT_ID_TYPE — 0: count all write channels 1: count sw_aw_count_id write channel only
  [3] GMAC_SW_AR_CNT_ID_TYPE — axi_perf counter id control 0: count all read channel id 1: count sw_ar_count_id read channel only
  [2] GMAC_SW_AXI_CNT_TYPE — axi_perf counter type 0: axi transfer test 1: ddr align transfer test
  [1] GMAC_SW_AXI_PERF_CLR — axi_perf clear bit 0: disable 1: enable
  [0] GMAC_SW_AXI_PERF_WORK — axi_perf enable bit 0: disable 1: enable
0xC004 GRF_GMAC_PERF_CON1 — gmac performance monitor control register
  [31:16] WRITE_ENABLE — bit0~15 write enable When bit 16=1, bit 0 can be written by software . When bit 16=0, bit 0 cannot be written by software; When bit 17=1, bit 1 can be written by software . When bit 17=0, bit 1 cannot be written by software; ...... When bit 31=1, bit 15 can be written by software . When bit 31=0, bit 15 cannot be written by software;
  [11:0] GMAC_SW_RD_LATENCY_THR — Axi read channel id for latency AXI_PERFormance test
0xC008 GRF_GMAC_PERF_CON2 — gmac performance monitor control register
  [31:16] WRITE_ENABLE — bit0~15 write enable When bit 16=1, bit 0 can be written by software . When bit 16=0, bit 0 cannot be written by software; When bit 17=1, bit 1 can be written by software . When bit 17=0, bit 1 cannot be written by software; ...... When bit 31=1, bit 15 can be written by software . When bit 31=0, bit 15 cannot be written by software;
  [11:8] GMAC_SW_AW_COUNT_ID — When sw_aw_cnt_id_type=1, only count the id designated by sw_aw_count_id
  [3:0] GMAC_SW_AR_COUNT_ID — When sw_ar_cnt_id_type=1, only count the id designated by sw_ar_count_id
0xC00C GRF_GMAC_PERF_RD_MAX_LATENCY_NUM — gmac performance monitor status register
  [12:0] RD_MAX_LATENCY_R — axi read max latency oaxi read max latency outpututput
0xC010 GRF_GMAC_PERF_RD_LATENCY_SAMP_NUM — gmac performance monitor status register
  [26:0] RD_LATENCY_SAMP_R — AXI read latency total sample number
0xC014 GRF_GMAC_PERF_RD_LATENCY_ACC_NUM — gmac performance monitor status register
  fields as GRF_HDCP22_PERF_RD_LATENCY_ACC_NUM
0xC018 GRF_GMAC_PERF_RD_AXI_TOTAL_BYTE — gmac performance monitor status register
  fields as GRF_HDCP22_PERF_RD_AXI_TOTAL_BYTE
0xC01C GRF_GMAC_PERF_WR_AXI_TOTAL_BYTE — gmac performance monitor status register
  fields as GRF_HDCP22_PERF_WR_AXI_TOTAL_BYTE
0xC020 GRF_GMAC_PERF_WORKING_CNT — gmac performance monitor status register
  [31:0] WORKING_CNT_R — working counter
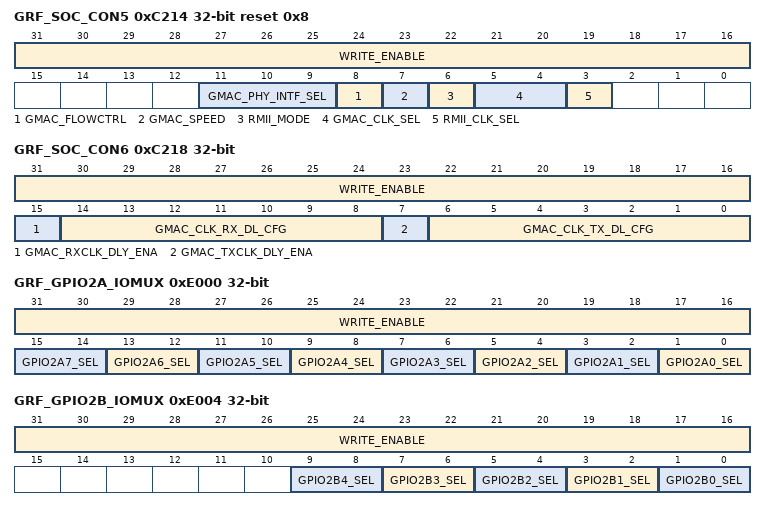
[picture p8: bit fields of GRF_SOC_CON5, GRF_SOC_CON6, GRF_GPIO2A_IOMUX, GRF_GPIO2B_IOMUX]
0xC214 GRF_SOC_CON5 reset 0x8 — SoC control register 5
  [31:16] WRITE_ENABLE — bit0~15 write enable When bit 16=1, bit 0 can be written by software . When bit 16=0, bit 0 cannot be written by software; When bit 17=1, bit 1 can be written by software . When bit 17=0, bit 1 cannot be written by software; ...... When bit 31=1, bit 15 can be written by software . When bit 31=0, bit 15 cannot be written by software;
  [11:9] GMAC_PHY_INTF_SEL — PHY interface select 3\'b001: RGMII 3\'b100: RMII All others: Reserved
  [8] GMAC_FLOWCTRL — GMAC transmit flow control When set high, instructs the GMAC to transmit PAUSE Control frames in Full-duplex mode. In Half-duplex mode, the GMAC enables the Back-pressure function until this signal is made low again
  [7] GMAC_SPEED — MAC speed 1\'b1: 100-Mbps 1\'b0: 10-Mbps
  [6] RMII_MODE — RMII mode selection 1\'b1: RMII mode 1\'b0: MII mode
  [5:4] GMAC_CLK_SEL — RGMII clock selection 2\'b00: 125MHz 2\'b11: 25MHz 2\'b10: 2.5MHz
  [3] RMII_CLK_SEL — RMII clock selection 1\'b1: 25MHz 1\'b0: 2.5MHz
0xC218 GRF_SOC_CON6 — SoC control register 6
  [31:16] WRITE_ENABLE — bit0~15 write enable When bit 16=1, bit 0 can be written by software . When bit 16=0, bit 0 cannot be written by software; When bit 17=1, bit 1 can be written by software . When bit 17=0, bit 1 cannot be written by software; ...... When bit 31=1, bit 15 can be written by software . When bit 31=0, bit 15 cannot be written by software;
  [15] GMAC_RXCLK_DLY_ENA — RGMII TX clock delayline enable 1\'b1: enable 1\'b0: disable
  [14:8] GMAC_CLK_RX_DL_CFG — RGMII RX clock delayline value
  [7] GMAC_TXCLK_DLY_ENA — RGMII TX clock delayline enable 1\'b1: enable 1\'b0: disable
  [6:0] GMAC_CLK_TX_DL_CFG — RGMII TX clock delayline value
0xE000 GRF_GPIO2A_IOMUX — GPIO2A iomux control
  [31:16] WRITE_ENABLE — bit0~15 write enable When bit 16=1, bit 0 can be written by software . When bit 16=0, bit 0 cannot be written by software; When bit 17=1, bit 1 can be written by software . When bit 17=0, bit 1 cannot be written by software; ...... When bit 31=1, bit 15 can be written by software . When bit 31=0, bit 15 cannot be written by software;
  [15:14] GPIO2A7_SEL — GPIO2A[7] iomux select 2\'b00: gpio 2\'b01: vop_data7 2\'b10: i2c7nfc_sda 2\'b11: cif_data7
  [13:12] GPIO2A6_SEL — GPIO2A[6] iomux select 2\'b00: gpio 2\'b01: vop_data6 2\'b10: uphyjtag_tms 2\'b11:cif_data6
  [11:10] GPIO2A5_SEL — GPIO2A[5] iomux select 2\'b00: gpio 2\'b01: vop_data5 2\'b10: uphyjtag_tck 2\'b11: cif_data5
  [9:8] GPIO2A4_SEL — GPIO2A[4] iomux select 2\'b00: gpio 2\'b01: vop_data4 2\'b10: uphyjtag_tdo 2\'b11: cif_data4
  [7:6] GPIO2A3_SEL — GPIO2A[3] iomux select 2\'b00: gpio 2\'b01: vop_data3 2\'b10: uphyjtag_tdi 2\'b11: cif_data3
  [5:4] GPIO2A2_SEL — GPIO2A[2] iomux select 2\'b00: gpio 2\'b01: vop_data2 2\'b10: uphyjtag_trstn 2\'b11: cif_data2
  [3:2] GPIO2A1_SEL — GPIO2A[1] iomux select 2\'b00: gpio 2\'b01: vop_data1 2\'b10: i2c2tp_scl 2\'b11: cif_data1
  [1:0] GPIO2A0_SEL — GPIO2A[0] iomux select 2\'b00: gpio 2\'b01: vop_data0 2\'b10: i2c2tp_sda 2\'b11: cif_data0
0xE004 GRF_GPIO2B_IOMUX — GPIO2B iomux control
  [31:16] WRITE_ENABLE — bit0~15 write enable When bit 16=1, bit 0 can be written by software . When bit 16=0, bit 0 cannot be written by software; When bit 17=1, bit 1 can be written by software . When bit 17=0, bit 1 cannot be written by software; ...... When bit 31=1, bit 15 can be written by software . When bit 31=0, bit 15 cannot be written by software;
  [9:8] GPIO2B4_SEL — GPIO2B[4] iomux select 2\'b00: gpio 2\'b01: spi2tpm_csn0 2\'b10: reserved 2\'b11: reserved
  [7:6] GPIO2B3_SEL — GPIO2B[3] iomux select 2\'b00: gpio 2\'b01: spi2tpm_clk 2\'b10: vop_den 2\'b11: cif_clkouta
  [5:4] GPIO2B2_SEL — GPIO2B[2] iomux select 2\'b00: gpio 2\'b01: spi2tpm_txd 2\'b10: i2c6tpm_scl 2\'b11: cif_clkin
  [3:2] GPIO2B1_SEL — GPIO2B[1] iomux select 2\'b00: gpio 2\'b01: spi2tpm_rxd 2\'b10: i2c6tpm_sda 2\'b11: cif_href
  [1:0] GPIO2B0_SEL — GPIO2B[0] iomux select 2\'b00: gpio 2\'b01: vop_dclk 2\'b10: i2c7nfc_scl 2\'b11: cif_vsync
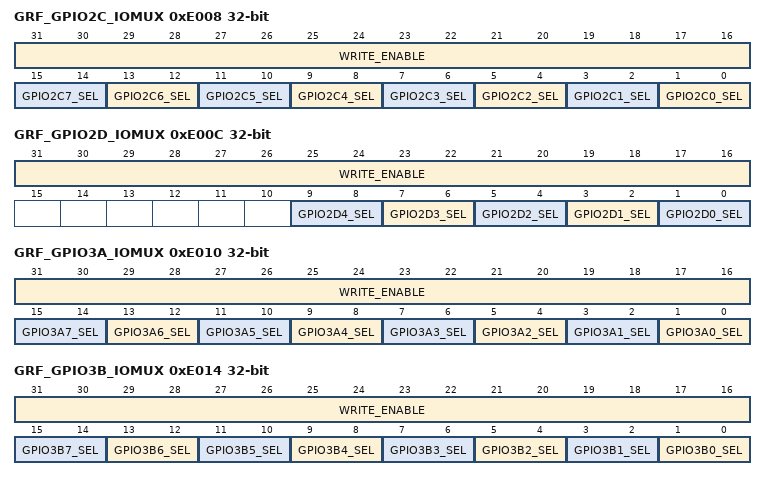
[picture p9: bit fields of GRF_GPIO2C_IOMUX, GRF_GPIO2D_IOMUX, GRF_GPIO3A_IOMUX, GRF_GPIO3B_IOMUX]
0xE008 GRF_GPIO2C_IOMUX — GPIO2C iomux control
  [31:16] WRITE_ENABLE — bit0~15 write enable When bit 16=1, bit 0 can be written by software . When bit 16=0, bit 0 cannot be written by software; When bit 17=1, bit 1 can be written by software . When bit 17=0, bit 1 cannot be written by software; ...... When bit 31=1, bit 15 can be written by software . When bit 31=0, bit 15 cannot be written by software;
  [15:14] GPIO2C7_SEL — GPIO2C[7] iomux select 2\'b00: gpio 2\'b01: sdio_data3 2\'b10: spi5expplus_csn0 2\'b11: reserved
  [13:12] GPIO2C6_SEL — GPIO2C[6] iomux select 2\'b00: gpio 2\'b01: sdio_data2 2\'b10: spi5expplus_clk 2\'b11: reserved
  [11:10] GPIO2C5_SEL — GPIO2C[5] iomux select 2\'b00: gpio 2\'b01: sdio_data1 2\'b10: spi5expplus_txd 2\'b11: reserved
  [9:8] GPIO2C4_SEL — GPIO2C[4] iomux select 2\'b00: gpio 2\'b01: sdio_data0 2\'b10: spi5expplus_rxd 2\'b11: reserved
  [7:6] GPIO2C3_SEL — GPIO2C[3] iomux select 2\'b00: gpio 2\'b01: uart0bt_rtsn 2\'b10: reserved 2\'b11: reserved
  [5:4] GPIO2C2_SEL — GPIO2C[2] iomux select 2\'b00: gpio 2\'b01: uart0bt_ctsn 2\'b10: reserved 2\'b11: reserved
  [3:2] GPIO2C1_SEL — GPIO2C[1] iomux select 2\'b00: gpio 2\'b01: uart0bt_sout 2\'b10: reserved 2\'b11: reserved
  [1:0] GPIO2C0_SEL — GPIO2C[0] iomux select 2\'b00: gpio 2\'b01: uart0bt_sin 2\'b10: reserved 2\'b11: reserved
0xE00C GRF_GPIO2D_IOMUX — GPIO2D iomux control
  [31:16] WRITE_ENABLE — bit0~15 write enable When bit 16=1, bit 0 can be written by software . When bit 16=0, bit 0 cannot be written by software; When bit 17=1, bit 1 can be written by software . When bit 17=0, bit 1 cannot be written by software; ...... When bit 31=1, bit 15 can be written by software . When bit 31=0, bit 15 cannot be written by software;
  [9:8] GPIO2D4_SEL — GPIO2D[4] iomux select 2\'b00: gpio 2\'b01: sdio_bkpwr 2\'b10: reserved 2\'b11: reserved
  [7:6] GPIO2D3_SEL — GPIO2D[3] iomux select 2\'b00: gpio 2\'b01: sdio_pwren 2\'b10: reserved 2\'b11: reserved
  [5:4] GPIO2D2_SEL — GPIO2D[2] iomux select 2\'b00: gpio 2\'b01: sdio_detectn 2\'b10: pcie_clkreqn 2\'b11: reserved
  [3:2] GPIO2D1_SEL — GPIO2D[1] iomux select 2\'b00: gpio 2\'b01: sdio_clkout 2\'b10: test_clkout1 2\'b11: reserved
  [1:0] GPIO2D0_SEL — GPIO2D[0] iomux select 2\'b00: gpio 2\'b01: sdio_cmd 2\'b10: reserved 2\'b11: reserved
0xE010 GRF_GPIO3A_IOMUX — GPIO3A iomux control
  [31:16] WRITE_ENABLE — bit0~15 write enable When bit 16=1, bit 0 can be written by software . When bit 16=0, bit 0 cannot be written by software; When bit 17=1, bit 1 can be written by software . When bit 17=0, bit 1 cannot be written by software; ...... When bit 31=1, bit 15 can be written by software . When bit 31=0, bit 15 cannot be written by software;
  [15:14] GPIO3A7_SEL — GPIO3A[7] iomux select 2\'b00: gpio 2\'b01: mac_rxd1 2\'b10: spi0norcodec_csn0 2\'b11: reserved
  [13:12] GPIO3A6_SEL — GPIO3A[6] iomux select 2\'b00: gpio 2\'b01: mac_rxd0 2\'b10: spi0norcodec_clk 2\'b11: reserved
  [11:10] GPIO3A5_SEL — GPIO3A[5] iomux select 2\'b00: gpio 2\'b01: mac_txd1 2\'b10: spi0norcodec_txd 2\'b11: reserved
  [9:8] GPIO3A4_SEL — GPIO3A[4] iomux select 2\'b00: gpio 2\'b01: mac_txd0 2\'b10: spi0norcodec_rxd 2\'b11: reserved
  [7:6] GPIO3A3_SEL — GPIO3A[3] iomux select 2\'b00: gpio 2\'b01: mac_rxd3 2\'b10: spi4exp_csn0 2\'b11: trace_data15
  [5:4] GPIO3A2_SEL — GPIO3A[2] iomux select 2\'b00: gpio 2\'b01: mac_rxd2 2\'b10: spi4exp_clk 2\'b11: trace_data14
  [3:2] GPIO3A1_SEL — GPIO3A[1] iomux select 2\'b00: gpio 2\'b01: mac_txd3 2\'b10: spi4exp_txd 2\'b11: trace_data13
  [1:0] GPIO3A0_SEL — GPIO3A[0] iomux select 2\'b00: gpio 2\'b01: mac_txd2 2\'b10: spi4exp_rxd 2\'b11: trace_data12
0xE014 GRF_GPIO3B_IOMUX — GPIO3B iomux control
  [31:16] WRITE_ENABLE — bit0~15 write enable When bit 16=1, bit 0 can be written by software . When bit 16=0, bit 0 cannot be written by software; When bit 17=1, bit 1 can be written by software . When bit 17=0, bit 1 cannot be written by software; ...... When bit 31=1, bit 15 can be written by software . When bit 31=0, bit 15 cannot be written by software;
  [15:14] GPIO3B7_SEL — GPIO3B[7] iomux select 2\'b00: gpio 2\'b01: mac_crs 2\'b10: uart3gps_sout 2\'b11: cif_clkoutb
  [13:12] GPIO3B6_SEL — GPIO3B[6] iomux select 2\'b00: gpio 2\'b01: mac_rxclk 2\'b10: uart3gps_sin 2\'b11: reserved
  [11:10] GPIO3B5_SEL — GPIO3B[5] iomux select 2\'b00: gpio 2\'b01: mac_mdio 2\'b10: uart1bb_sout 2\'b11: reserved
  [9:8] GPIO3B4_SEL — GPIO3B[4] iomux select 2\'b00: gpio 2\'b01: mac_txen 2\'b10: uart1bb_sin 2\'b11: reserved
  [7:6] GPIO3B3_SEL — GPIO3B[3] iomux select 2\'b00: gpio 2\'b01: mac_clk 2\'b10: i2c5trackpad_scl 2\'b11: reserved
  [5:4] GPIO3B2_SEL — GPIO3B[2] iomux select 2\'b00: gpio 2\'b01: mac_rxer 2\'b10: i2c5trackpad_sda 2\'b11: reserved
  [3:2] GPIO3B1_SEL — GPIO3B[1] iomux select 2\'b00: gpio 2\'b01: mac_rxdv 2\'b10: reserved 2\'b11: reserved
  [1:0] GPIO3B0_SEL — GPIO3B[0] iomux select 2\'b00: gpio 2\'b01: mac_mdc 2\'b10: spi0norcodec_csn1 2\'b11: reserved
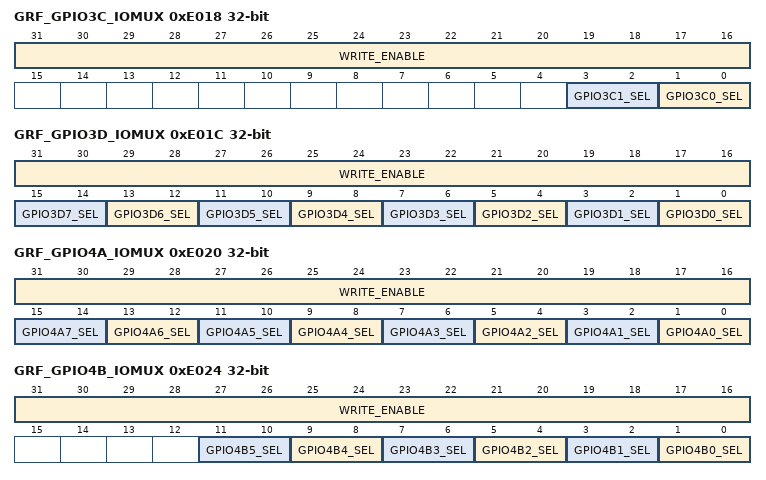
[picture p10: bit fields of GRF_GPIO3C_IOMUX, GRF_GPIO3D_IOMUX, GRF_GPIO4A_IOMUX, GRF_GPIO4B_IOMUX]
0xE018 GRF_GPIO3C_IOMUX — GPIO3C iomux control
  [31:16] WRITE_ENABLE — bit0~15 write enable When bit 16=1, bit 0 can be written by software . When bit 16=0, bit 0 cannot be written by software; When bit 17=1, bit 1 can be written by software . When bit 17=0, bit 1 cannot be written by software; ...... When bit 31=1, bit 15 can be written by software . When bit 31=0, bit 15 cannot be written by software;
  [3:2] GPIO3C1_SEL — GPIO3C[1] iomux select 2\'b00: gpio 2\'b01: mac_txclk 2\'b10: uart3gps_rtsn 2\'b11: reserved
  [1:0] GPIO3C0_SEL — GPIO3C[0] iomux select 2\'b00: gpio 2\'b01: mac_col 2\'b10: uart3gps_ctsn 2\'b11: spdif_txb
0xE01C GRF_GPIO3D_IOMUX — GPIO3D iomux control
  [31:16] WRITE_ENABLE — bit0~15 write enable When bit 16=1, bit 0 can be written by software . When bit 16=0, bit 0 cannot be written by software; When bit 17=1, bit 1 can be written by software . When bit 17=0, bit 1 cannot be written by software; ...... When bit 31=1, bit 15 can be written by software . When bit 31=0, bit 15 cannot be written by software;
  [15:14] GPIO3D7_SEL — GPIO3D[7] iomux select 2\'b00: gpio 2\'b01: i2s0_sdo0 2\'b10: trace_data7 2\'b11: a53l2_wfi
  [13:12] GPIO3D6_SEL — GPIO3D[6] iomux select 2\'b00: gpio 2\'b01: i2s0_sdi3sdo1 2\'b10: trace_data6 2\'b11: a72l2_wfi
  [11:10] GPIO3D5_SEL — GPIO3D[5] iomux select 2\'b00: gpio 2\'b01: i2s0_sdi2sdo2 2\'b10: trace_data5 2\'b11: a53core3_wfi
  [9:8] GPIO3D4_SEL — GPIO3D[4] iomux select 2\'b00: gpio 2\'b01: i2s0_sdi1sdo3 2\'b10: trace_data4 2\'b11: a53core2_wfi
  [7:6] GPIO3D3_SEL — GPIO3D[3] iomux select 2\'b00: gpio 2\'b01: i2s0_sdi0 2\'b10: trace_data3 2\'b11: a53core1_wfi
  [5:4] GPIO3D2_SEL — GPIO3D[2] iomux select 2\'b00: gpio 2\'b01: i2s0_lrcktx 2\'b10: trace_data2 2\'b11: a53core0_wfi
  [3:2] GPIO3D1_SEL — GPIO3D[1] iomux select 2\'b00: gpio 2\'b01: i2s0_lrckrx 2\'b10: trace_data1 2\'b11: a72core1_wfi
  [1:0] GPIO3D0_SEL — GPIO3D[0] iomux select 2\'b00: gpio 2\'b01: i2s0_sclk 2\'b10: trace_data0 2\'b11: a72core0_wfi
0xE020 GRF_GPIO4A_IOMUX — GPIO4A iomux control
  [31:16] WRITE_ENABLE — bit0~15 write enable When bit 16=1, bit 0 can be written by software . When bit 16=0, bit 0 cannot be written by software; When bit 17=1, bit 1 can be written by software . When bit 17=0, bit 1 cannot be written by software; ...... When bit 31=1, bit 15 can be written by software . When bit 31=0, bit 15 cannot be written by software;
  [15:14] GPIO4A7_SEL — GPIO4A[7] iomux select 2\'b00: gpio 2\'b01: i2s1_sdo0 2\'b10: reserved 2\'b11: reserved
  [13:12] GPIO4A6_SEL — GPIO4A[6] iomux select 2\'b00: gpio 2\'b01: i2s1_sdi0 2\'b10: reserved 2\'b11: reserved
  [11:10] GPIO4A5_SEL — GPIO4A[5] iomux select 2\'b00: gpio 2\'b01: i2s1_lrcktx 2\'b10: trace_data11 2\'b11: reserved
  [9:8] GPIO4A4_SEL — GPIO4A[4] iomux select 2\'b00: gpio 2\'b01: i2s1_lrckrx 2\'b10: trace_data10 2\'b11: reserved
  [7:6] GPIO4A3_SEL — GPIO4A[3] iomux select 2\'b00: gpio 2\'b01: i2s1_sclk 2\'b10: trace_data9 2\'b11: reserved
  [5:4] GPIO4A2_SEL — GPIO4A[2] iomux select 2\'b00: gpio 2\'b01: i2c1audiocam_scl 2\'b10: trace_data8 2\'b11: reserved
  [3:2] GPIO4A1_SEL — GPIO4A[1] iomux select 2\'b00: gpio 2\'b01: i2c1audiocam_sda 2\'b10: trace_clk 2\'b11: reserved
  [1:0] GPIO4A0_SEL — GPIO4A[0] iomux select 2\'b00: gpio 2\'b01: i2s_clk 2\'b10: trace_ctl 2\'b11: lpm0_wfi
0xE024 GRF_GPIO4B_IOMUX — GPIO4B iomux control
  [31:16] WRITE_ENABLE — bit0~15 write enable When bit 16=1, bit 0 can be written by software . When bit 16=0, bit 0 cannot be written by software; When bit 17=1, bit 1 can be written by software . When bit 17=0, bit 1 cannot be written by software; ...... When bit 31=1, bit 15 can be written by software . When bit 31=0, bit 15 cannot be written by software;
  [11:10] GPIO4B5_SEL — GPIO4B[5] iomux select 2\'b00: gpio 2\'b01: sdmmc_cmd 2\'b10: mcujtag_tms 2\'b11: hdcpjtag_tms
  [9:8] GPIO4B4_SEL — GPIO4B[4] iomux select 2\'b00: gpio 2\'b01: sdmmc_clkout 2\'b10: mcujtag_tck 2\'b11: hdcpjtag_tck
  [7:6] GPIO4B3_SEL — GPIO4B[3] iomux select 2\'b00: gpio 2\'b01: sdmmc_data3 2\'b10: cxcsjtag_tms 2\'b11: hdcpjtag_tdo
  [5:4] GPIO4B2_SEL — GPIO4B[2] iomux select 2\'b00: gpio 2\'b01: sdmmc_data2 2\'b10: cxcsjtag_tck 2\'b11: hdcpjtag_tdi
  [3:2] GPIO4B1_SEL — GPIO4B[1] iomux select 2\'b00: gpio 2\'b01: sdmmc_data1 2\'b10: uart2dbga_sout 2\'b11: hdcpjtag_trstn
  [1:0] GPIO4B0_SEL — GPIO4B[0] iomux select 2\'b00: gpio 2\'b01: sdmmc_data0 2\'b10: uart2dbga_sin 2\'b11: reserved
